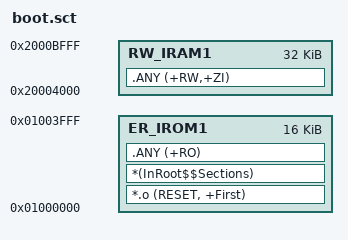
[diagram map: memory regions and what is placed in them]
; Bootloader scatter: 16KB @ 0x01000000

LR_IROM1 0x01000000 0x00004000  {
  ER_IROM1 0x01000000 0x00004000  {
   *.o (RESET, +First)
   *(InRoot$$Sections)
   .ANY (+RO)
  }
  RW_IRAM1 0x20004000 0x00008000  {
   .ANY (+RW,+ZI)
  }
}
